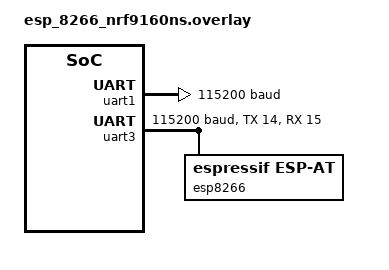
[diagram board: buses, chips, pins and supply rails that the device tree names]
/* Copyright (c) 2021 Nordic Semiconductor ASA
 *
 * SPDX-License-Identifier: LicenseRef-Nordic-5-Clause
 */

&uart1 {
	status = "okay";
	current-speed = <115200>;
	rts-pin = <0xffffffff>;
	cts-pin = <0xffffffff>;
};

&uart3 {
	status = "okay";
	current-speed = <115200>;
	tx-pin = < 0xe >;
	rx-pin = < 0xf >;
	rts-pin = <0xffffffff>;
	cts-pin = <0xffffffff>;

	esp8266 {
		compatible = "espressif,esp-at";
		label = "esp8266";
		status = "okay";
	};
};
